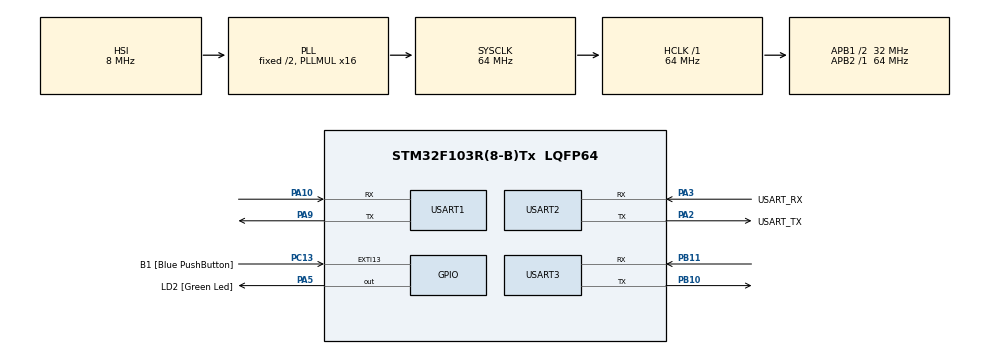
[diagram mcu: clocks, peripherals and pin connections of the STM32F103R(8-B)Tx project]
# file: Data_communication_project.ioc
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Dma.Request0=USART1_RX
Dma.Request1=USART2_RX
Dma.USART1_RX.0.Direction=DMA_PERIPH_TO_MEMORY
Dma.USART1_RX.0.Instance=DMA1_Channel5
Dma.USART1_RX.0.MemDataAlignment=DMA_MDATAALIGN_BYTE
Dma.USART1_RX.0.MemInc=DMA_MINC_ENABLE
Dma.USART1_RX.0.Mode=DMA_CIRCULAR
Dma.USART1_RX.0.PeriphDataAlignment=DMA_PDATAALIGN_BYTE
Dma.USART1_RX.0.PeriphInc=DMA_PINC_DISABLE
Dma.USART1_RX.0.Priority=DMA_PRIORITY_LOW
Dma.USART2_RX.1.Direction=DMA_PERIPH_TO_MEMORY
Dma.USART2_RX.1.Instance=DMA1_Channel6
Dma.USART2_RX.1.MemDataAlignment=DMA_MDATAALIGN_BYTE
Dma.USART2_RX.1.MemInc=DMA_MINC_ENABLE
Dma.USART2_RX.1.Mode=DMA_CIRCULAR
Dma.USART2_RX.1.PeriphDataAlignment=DMA_PDATAALIGN_BYTE
Dma.USART2_RX.1.PeriphInc=DMA_PINC_DISABLE
Dma.USART2_RX.1.Priority=DMA_PRIORITY_LOW
FREERTOS.Queues01=UARTQueue,16,QUEUE_t,0,Static,UARTQueueBuffer,UARTQueueControlBlock
FREERTOS.Tasks01=defaultTask,24,128,StartDefaultTask,Default,NULL,Static,defaultTaskBuffer,defaultTaskControlBlock;UART1Task,8,128,StartUART1Task,Default,NULL,Static,UART1TaskBuffer,UART1TaskControlBlock;UART2Task,8,128,StartUART2Task,Default,NULL,Static,UART2TaskBuffer,UART2TaskControlBlock;UART3Task,8,128,StartUART3Task,Default,NULL,Static,UART3TaskBuffer,UART3TaskControlBlock
FREERTOS.configTOTAL_HEAP_SIZE=4096
Mcu.Family=STM32F1
Mcu.Name=STM32F103R(8-B)Tx
Mcu.Package=LQFP64
NVIC.DMA1_Channel5_IRQn=true\:5\:0\:false\:false\:true\:true\:false\:true\:true
NVIC.DMA1_Channel6_IRQn=true\:5\:0\:false\:false\:true\:true\:false\:true\:true
NVIC.EXTI15_10_IRQn=true\:5\:0\:false\:false\:true\:true\:true\:true\:true
NVIC.PriorityGroup=NVIC_PRIORITYGROUP_4
NVIC.TIM4_IRQn=true\:15\:0\:false\:false\:true\:false\:false\:true\:true
NVIC.TimeBase=TIM4_IRQn
NVIC.TimeBaseIP=TIM4
NVIC.USART1_IRQn=true\:5\:0\:false\:false\:true\:true\:true\:true\:true
NVIC.USART2_IRQn=true\:5\:0\:false\:false\:true\:true\:true\:true\:true
NVIC.USART3_IRQn=true\:5\:0\:false\:false\:true\:true\:true\:true\:true
PA10.Mode=Asynchronous
PA10.Signal=USART1_RX
PA13.GPIO_Label=TMS
PA13.Mode=Serial_Wire
PA13.Signal=SYS_JTMS-SWDIO
PA14.GPIO_Label=TCK
PA14.Mode=Serial_Wire
PA14.Signal=SYS_JTCK-SWCLK
PA2.GPIO_Label=USART_TX
PA2.GPIO_Mode=GPIO_MODE_AF_PP
PA2.GPIO_PuPd=GPIO_NOPULL
PA2.GPIO_Speed=GPIO_SPEED_FREQ_LOW
PA2.Mode=Asynchronous
PA2.Signal=USART2_TX
PA3.GPIO_Label=USART_RX
PA3.GPIO_Mode=GPIO_MODE_AF_PP
PA3.GPIO_PuPd=GPIO_NOPULL
PA3.GPIO_Speed=GPIO_SPEED_FREQ_LOW
PA3.Mode=Asynchronous
PA3.Signal=USART2_RX
PA5.GPIO_Label=LD2 [Green Led]
PA5.GPIO_ModeDefaultOutputPP=GPIO_MODE_OUTPUT_PP
PA5.GPIO_PuPd=GPIO_NOPULL
PA5.GPIO_Speed=GPIO_SPEED_FREQ_LOW
PA5.Signal=GPIO_Output
PA9.Mode=Asynchronous
PA9.Signal=USART1_TX
PB10.Mode=Asynchronous
PB10.Signal=USART3_TX
PB11.Mode=Asynchronous
PB11.Signal=USART3_RX
PB3.GPIO_Label=SWO
PB3.Signal=SYS_JTDO-TRACESWO
PC13-TAMPER-RTC.GPIO_Label=B1 [Blue PushButton]
PC13-TAMPER-RTC.GPIO_PuPd=GPIO_NOPULL
PC13-TAMPER-RTC.Signal=GPXTI13
PC14-OSC32_IN.Mode=LSE-External-Oscillator
PC14-OSC32_IN.Signal=RCC_OSC32_IN
PC15-OSC32_OUT.Mode=LSE-External-Oscillator
PC15-OSC32_OUT.Signal=RCC_OSC32_OUT
PD0-OSC_IN.Mode=HSE-External-Clock-Source
PD0-OSC_IN.Signal=RCC_OSC_IN
PD1-OSC_OUT.Mode=HSE-External-Clock-Source
PD1-OSC_OUT.Signal=RCC_OSC_OUT
ProjectManager.HeapSize=0x200
ProjectManager.StackSize=0x400
ProjectManager.TargetToolchain=STM32CubeIDE
RCC.AHBFreq_Value=64000000
RCC.APB1CLKDivider=RCC_HCLK_DIV2
RCC.APB1Freq_Value=32000000
RCC.APB1TimFreq_Value=64000000
RCC.APB2Freq_Value=64000000
RCC.APB2TimFreq_Value=64000000
RCC.HCLKFreq_Value=64000000
RCC.PLLMUL=RCC_PLL_MUL16
RCC.RTCClockSelection=RCC_RTCCLKSOURCE_LSE
RCC.SYSCLKFreq_VALUE=64000000
RCC.SYSCLKSource=RCC_SYSCLKSOURCE_PLLCLK
RCC.USBFreq_Value=64000000
USART1.VirtualMode=VM_ASYNC
USART2.VirtualMode=VM_ASYNC
USART3.VirtualMode=VM_ASYNC
VP_FREERTOS_VS_CMSIS_V2.Mode=CMSIS_V2
VP_SYS_VS_tim4.Mode=TIM4
board=NUCLEO-F103RB

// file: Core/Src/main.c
/* USER CODE BEGIN Header */
/**
  ******************************************************************************
  * @file           : main.c
  * @brief          : Main program body
  ******************************************************************************
  * @attention
  *
  * Copyright (c) 2025 STMicroelectronics.
  * All rights reserved.
  *
  * This software is licensed under terms that can be found in the LICENSE file
  * in the root directory of this software component.
  * If no LICENSE file comes with this software, it is provided AS-IS.
  *
  ******************************************************************************
  */
/* USER CODE END Header */
#include "main.h"
#include "cmsis_os.h"
#include "dma.h"
#include "usart.h"
#include "gpio.h"

void SystemClock_Config(void);
void MX_FREERTOS_Init(void);

int main(void)
{

  /* MCU Configuration--------------------------------------------------------*/

  /* Reset of all peripherals, Initializes the Flash interface and the Systick. */
  HAL_Init();

  /* Configure the system clock */
  SystemClock_Config();

  /* Initialize all configured peripherals */
  MX_GPIO_Init();
  MX_DMA_Init();
  MX_USART1_UART_Init();
  MX_USART2_UART_Init();
  MX_USART3_UART_Init();

  /* Init scheduler */
  osKernelInitialize();  /* Call init function for freertos objects (in freertos.c) */
  MX_FREERTOS_Init();
  HAL_UART_Transmit(&huart3, (uint8_t*)"Already \r\n", 10, 100);

  /* Start scheduler */
  osKernelStart();

  /* We should never get here as control is now taken by the scheduler */
  /* Infinite loop */
  while (1)
  {

  }
}

void SystemClock_Config(void)
{
  RCC_OscInitTypeDef RCC_OscInitStruct = {0};
  RCC_ClkInitTypeDef RCC_ClkInitStruct = {0};

  /** Initializes the RCC Oscillators according to the specified parameters
  * in the RCC_OscInitTypeDef structure.
  */
  RCC_OscInitStruct.OscillatorType = RCC_OSCILLATORTYPE_HSI;
  RCC_OscInitStruct.HSIState = RCC_HSI_ON;
  RCC_OscInitStruct.HSICalibrationValue = RCC_HSICALIBRATION_DEFAULT;
  RCC_OscInitStruct.PLL.PLLState = RCC_PLL_ON;
  RCC_OscInitStruct.PLL.PLLSource = RCC_PLLSOURCE_HSI_DIV2;
  RCC_OscInitStruct.PLL.PLLMUL = RCC_PLL_MUL16;
  if (HAL_RCC_OscConfig(&RCC_OscInitStruct) != HAL_OK)
  {
    Error_Handler();
  }

  /** Initializes the CPU, AHB and APB buses clocks
  */
  RCC_ClkInitStruct.ClockType = RCC_CLOCKTYPE_HCLK|RCC_CLOCKTYPE_SYSCLK
                              |RCC_CLOCKTYPE_PCLK1|RCC_CLOCKTYPE_PCLK2;
  RCC_ClkInitStruct.SYSCLKSource = RCC_SYSCLKSOURCE_PLLCLK;
  RCC_ClkInitStruct.AHBCLKDivider = RCC_SYSCLK_DIV1;
  RCC_ClkInitStruct.APB1CLKDivider = RCC_HCLK_DIV2;
  RCC_ClkInitStruct.APB2CLKDivider = RCC_HCLK_DIV1;

  if (HAL_RCC_ClockConfig(&RCC_ClkInitStruct, FLASH_LATENCY_2) != HAL_OK)
  {
    Error_Handler();
  }
}

void HAL_TIM_PeriodElapsedCallback(TIM_HandleTypeDef *htim)
{
  if (htim->Instance == TIM4) {
    HAL_IncTick();
  }
}

void Error_Handler(void)
{
  __disable_irq();
  while (1)
  {
  }
}

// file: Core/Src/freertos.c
/* USER CODE BEGIN Header */
/**
  ******************************************************************************
  * File Name          : freertos.c
  * Description        : Code for freertos applications
  ******************************************************************************
  * @attention
  *
  * Copyright (c) 2025 STMicroelectronics.
  * All rights reserved.
  *
  * This software is licensed under terms that can be found in the LICENSE file
  * in the root directory of this software component.
  * If no LICENSE file comes with this software, it is provided AS-IS.
  *
  ******************************************************************************
  */
/* USER CODE END Header */

#include <stdio.h>
#include "FreeRTOS.h"
#include "task.h"
#include "main.h"
#include "cmsis_os.h"
#include "fifo.h"
#include "usart.h"
#include "MAVLinkV1.h"

/* USER CODE BEGIN Includes */
extern FIFO_Buffer_t uart1_fifo;
extern FIFO_Buffer_t uart2_fifo;

/* USER CODE END Includes */

typedef StaticTask_t osStaticThreadDef_t;
typedef StaticQueue_t osStaticMessageQDef_t;
/* USER CODE BEGIN PTD */
typedef struct {
  uint8_t data[300];
  uint16_t len;
} QUEUE_t;
#include "semphr.h"
SemaphoreHandle_t xUART1Sem;
SemaphoreHandle_t xUART2Sem;
SemaphoreHandle_t xUART3TxDoneSem; // Semaphore for UART3

/* USER CODE END PTD */

/* Definitions for defaultTask */
osThreadId_t defaultTaskHandle;
uint32_t defaultTaskBuffer[ 128 ];
osStaticThreadDef_t defaultTaskControlBlock;
const osThreadAttr_t defaultTask_attributes = {
  .name = "defaultTask",
  .cb_mem = &defaultTaskControlBlock,
  .cb_size = sizeof(defaultTaskControlBlock),
  .stack_mem = &defaultTaskBuffer[0],
  .stack_size = sizeof(defaultTaskBuffer),
  .priority = (osPriority_t) osPriorityNormal,
};
/* Definitions for UART1Task */
osThreadId_t UART1TaskHandle;
uint32_t UART1TaskBuffer[ 300 ];
osStaticThreadDef_t UART1TaskControlBlock;
const osThreadAttr_t UART1Task_attributes = {
  .name = "UART1Task",
  .cb_mem = &UART1TaskControlBlock,
  .cb_size = sizeof(UART1TaskControlBlock),
  .stack_mem = &UART1TaskBuffer[0],
  .stack_size = sizeof(UART1TaskBuffer),
  .priority = (osPriority_t) osPriorityLow,
};
/* Definitions for UART2Task */
osThreadId_t UART2TaskHandle;
uint32_t UART2TaskBuffer[ 300 ];
osStaticThreadDef_t UART2TaskControlBlock;
const osThreadAttr_t UART2Task_attributes = {
  .name = "UART2Task",
  .cb_mem = &UART2TaskControlBlock,
  .cb_size = sizeof(UART2TaskControlBlock),
  .stack_mem = &UART2TaskBuffer[0],
  .stack_size = sizeof(UART2TaskBuffer),
  .priority = (osPriority_t) osPriorityAboveNormal,
};
/* Definitions for UART3Task */
osThreadId_t UART3TaskHandle;
uint32_t UART3TaskBuffer[ 300 ];
osStaticThreadDef_t UART3TaskControlBlock;
const osThreadAttr_t UART3Task_attributes = {
  .name = "UART3Task",
  .cb_mem = &UART3TaskControlBlock,
  .cb_size = sizeof(UART3TaskControlBlock),
  .stack_mem = &UART3TaskBuffer[0],
  .stack_size = sizeof(UART3TaskBuffer),
  .priority = (osPriority_t) osPriorityHigh,
};
/* Definitions for UARTQueue */
osMessageQueueId_t UARTQueueHandle;
uint8_t UARTQueueBuffer[ 16 * sizeof( QUEUE_t ) ];
osStaticMessageQDef_t UARTQueueControlBlock;
const osMessageQueueAttr_t UARTQueue_attributes = {
  .name = "UARTQueue",
  .cb_mem = &UARTQueueControlBlock,
  .cb_size = sizeof(UARTQueueControlBlock),
  .mq_mem = &UARTQueueBuffer,
  .mq_size = sizeof(UARTQueueBuffer)
};

void StartDefaultTask(void *argument);
void StartUART1Task(void *argument);
void StartUART2Task(void *argument);
void StartUART3Task(void *argument);

void MX_FREERTOS_Init(void); /* (MISRA C 2004 rule 8.1) */

void MX_FREERTOS_Init(void) {

  /* Create the queue(s) */
  /* creation of UARTQueue */
  UARTQueueHandle = osMessageQueueNew (16, sizeof(QUEUE_t), &UARTQueue_attributes);

  /* Create the thread(s) */
  /* creation of defaultTask */
  defaultTaskHandle = osThreadNew(StartDefaultTask, NULL, &defaultTask_attributes);

  /* creation of UART1Task */
  UART1TaskHandle = osThreadNew(StartUART1Task, NULL, &UART1Task_attributes);

  /* creation of UART2Task */
  UART2TaskHandle = osThreadNew(StartUART2Task, NULL, &UART2Task_attributes);

  /* creation of UART3Task */
  UART3TaskHandle = osThreadNew(StartUART3Task, NULL, &UART3Task_attributes);

  xUART1Sem = xSemaphoreCreateBinary();
  xUART2Sem = xSemaphoreCreateBinary();
  xUART3TxDoneSem = xSemaphoreCreateBinary();

}

void StartDefaultTask(void *argument)
{
  for(;;)
  {
    osDelay(1);
  }
}

void StartUART1Task(void *argument)
{
    static mavlink_message_t mav_msg;
    static mavlink_state_t mav_state = MAVLINK_STATE_IDLE;
    QUEUE_t msg;
    uint8_t byte;
//    uint32_t ulNotificationValue = 0;

    for (;;)
    {
//        xTaskNotifyWait(0x00, 0xFFFFFFFF, &ulNotificationValue, portMAX_DELAY);
    	xSemaphoreTake(xUART1Sem, portMAX_DELAY);

        do {
            int available = FIFO_Available(&uart1_fifo);
            for (int i = 0; i < available; i++)
            {
                FIFO_Read(&uart1_fifo, &byte, 1);

                if (mavlink_parse_byte(&mav_state, &mav_msg, byte))
                {
                    int payload_len = mav_msg.len;
                    char payload_str[256];
                    memcpy(payload_str, mav_msg.payload, payload_len);
                    payload_str[payload_len] = '\0';

                    msg.len = snprintf((char*)msg.data, sizeof(msg.data), "UART1: %s\r\n", payload_str);
                    osMessageQueuePut(UARTQueueHandle, &msg, 0, 20);
                }
            }
        } while (FIFO_Available(&uart1_fifo) > 0);
    }
}

void StartUART2Task(void *argument)
{
    static mavlink_message_t mav_msg;
    static mavlink_state_t mav_state = MAVLINK_STATE_IDLE;
    QUEUE_t msg;
    uint8_t byte;
//    uint32_t ulNotificationValue = 0;

    for (;;)
    {
//        xTaskNotifyWait(0x00, 0xFFFFFFFF, &ulNotificationValue, portMAX_DELAY);
    	xSemaphoreTake(xUART2Sem, portMAX_DELAY);

        do {
            int available = FIFO_Available(&uart2_fifo);
            for (int i = 0; i < available; i++)
            {
                FIFO_Read(&uart2_fifo, &byte, 1);

                if (mavlink_parse_byte(&mav_state, &mav_msg, byte))
                {
                    int payload_len = mav_msg.len;
                    char payload_str[256];
                    memcpy(payload_str, mav_msg.payload, payload_len);
                    payload_str[payload_len] = '\0';

                    msg.len = snprintf((char*)msg.data, sizeof(msg.data), "UART2: %s\r\n", payload_str);
                    osMessageQueuePut(UARTQueueHandle, &msg, 0, 20);
                }
            }
        } while (FIFO_Available(&uart2_fifo) > 0);
    }
}

//void StartUART3Task(void *argument)
//{
//    QUEUE_t msg;
//
//    for (;;)
//    {
//        if (osMessageQueueGet(UARTQueueHandle, &msg, NULL, osWaitForever) == osOK)
//        {
//            HAL_GPIO_TogglePin(LD2_GPIO_Port, LD2_Pin); // test hoạt động
//            HAL_UART_Transmit(&huart3, msg.data, msg.len, 50);
//        }
//    }
//}

void StartUART3Task(void *argument) // StartUART3 Transmit with DMA
{
    QUEUE_t msg;

    for (;;)
    {
        if (osMessageQueueGet(UARTQueueHandle, &msg, NULL, osWaitForever) == osOK)
        {
            HAL_GPIO_TogglePin(LD2_GPIO_Port, LD2_Pin); // Kiểm tra hoạt động
            if (HAL_UART_Transmit_DMA(&huart3, msg.data, msg.len) == HAL_OK)
            {
                // Đợi DMA TX xong bằng semaphore
                xSemaphoreTake(xUART3TxDoneSem, portMAX_DELAY);
            }
        }
    }
}
